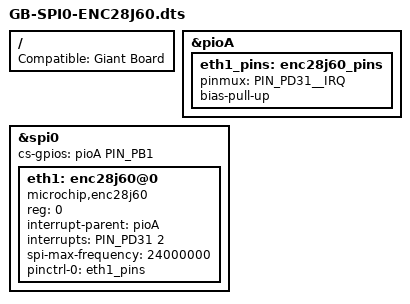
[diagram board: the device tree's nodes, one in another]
/dts-v1/;
/plugin/;

#include "sama5d2-pinfunc.h"

/ {
	Compatible = "Giant Board";

	fragment@0 {
		target = <&pioA>;
		__overlay__ {
			eth1_pins: enc28j60_pins {
				pinmux = <PIN_PD31__IRQ>;
				bias-pull-up;
			};
		};
	};
	
	fragment@1 {
		target = <&spi0>;
		__overlay__ {
			#address-cells = <1>;
			#size-cells = <0>;
			cs-gpios = <&pioA PIN_PB1 0>;
			status = "okay";
			eth1: enc28j60@0 {
				compatible = "microchip,enc28j60";
				reg = <0>;
				interrupt-parent = <&pioA>;
				interrupts = <PIN_PD31 2>; 
				spi-max-frequency = <24000000>;
				pinctrl-names = "default";
				pinctrl-0 = <&eth1_pins>;
			};
		};
	};
};
